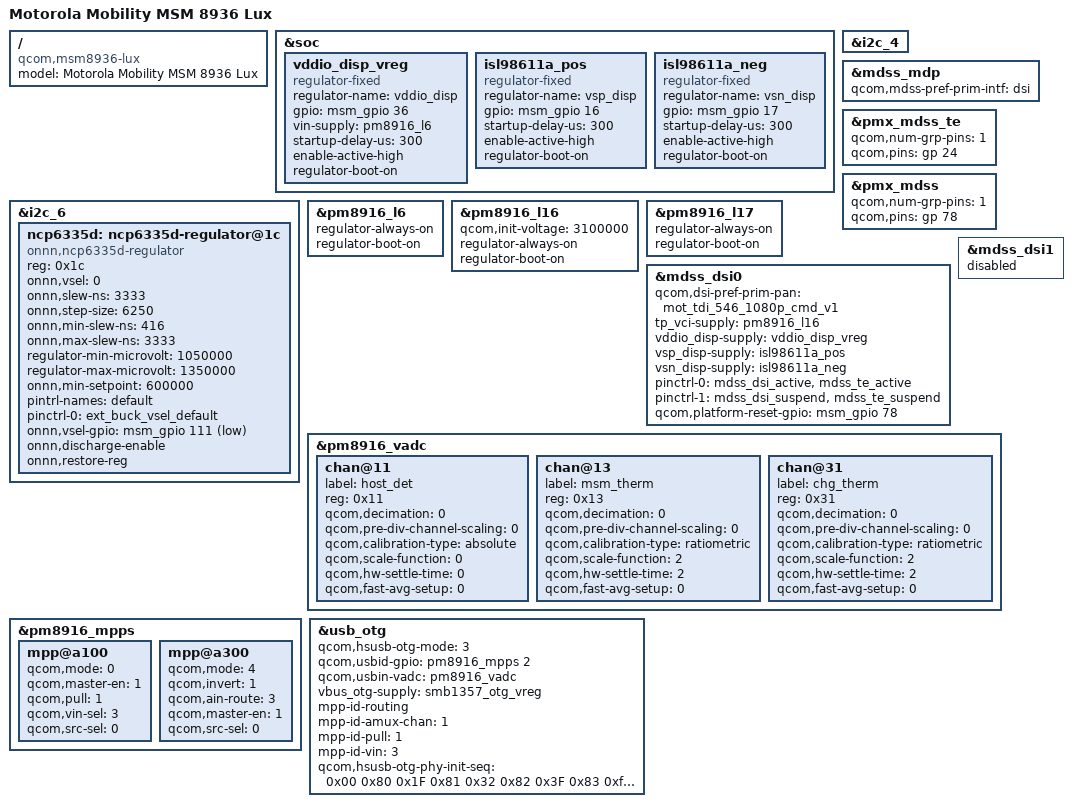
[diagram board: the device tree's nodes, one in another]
/* Copyright (c) 2014, Motorola Mobility LLC. All rights reserved.
*
* This program is free software; you can redistribute it and/or modify
* it under the terms of the GNU General Public License version 2 and
* only version 2 as published by the Free Software Foundation.
*
* This program is distributed in the hope that it will be useful,
* but WITHOUT ANY WARRANTY; without even the implied warranty of
* MERCHANTABILITY or FITNESS FOR A PARTICULAR PURPOSE.  See the
* GNU General Public License for more details.
*/

#include "msm8939-moto-common.dtsi"
#include "dsi-panel-mot-tdi-546-1080p-cmd.dtsi"
#include "dsi-panel-mot-dummy-qhd-video.dtsi"

/ {
	model = "Motorola Mobility MSM 8936 Lux";
	compatible = "qcom,msm8936-lux", "qcom,msm8936-moto", "qcom,msm8936";
};

&soc {
	vddio_disp_vreg: vddio_disp_vreg {
		compatible = "regulator-fixed";
		regulator-name = "vddio_disp";
		gpio = <&msm_gpio 36 0>;
		vin-supply = <&pm8916_l6>;
		startup-delay-us = <300>;
		enable-active-high;
		regulator-boot-on;
	};

	isl98611a_pos: isl98611a_pos {
		compatible = "regulator-fixed";
		regulator-name = "vsp_disp";
		gpio = <&msm_gpio 16 0>;
		startup-delay-us = <300>;
		enable-active-high;
		regulator-boot-on;
	};

	isl98611a_neg: isl98611a_neg {
		compatible = "regulator-fixed";
		regulator-name = "vsn_disp";
		gpio = <&msm_gpio 17 0>;
		startup-delay-us = <300>;
		enable-active-high;
		regulator-boot-on;
	};
};

&i2c_4 {
	/delete-node/ ncp6335d-regulator@1c;
};

&i2c_6 {

	ncp6335d: ncp6335d-regulator@1c {
		compatible = "onnn,ncp6335d-regulator";
		reg = <0x1c>;
		onnn,vsel = <0>;
		onnn,slew-ns = <3333>;
		onnn,step-size = <6250>;
		onnn,min-slew-ns = <416>;
		onnn,max-slew-ns = <3333>;
		regulator-min-microvolt = <1050000>;
		regulator-max-microvolt = <1350000>;
		onnn,min-setpoint = <600000>;
		pintrl-names = "default";
		pinctrl-0 = <&ext_buck_vsel_default>;
		onnn,vsel-gpio = <&msm_gpio 111 1>;
		onnn,discharge-enable;
		onnn,restore-reg;
	};
};


&mdss_mdp {
	qcom,mdss-pref-prim-intf = "dsi";
};

&pmx_mdss_te {
	qcom,num-grp-pins = <1>;
	qcom,pins = <&gp 24>;
};

&pmx_mdss {
	qcom,num-grp-pins = <1>;
	qcom,pins = <&gp 78>;
};

&pm8916_l6 {
	regulator-always-on;
	regulator-boot-on;
};

&pm8916_l16 {
	qcom,init-voltage = <3100000>;
	regulator-always-on;
	regulator-boot-on;
};

&pm8916_l17 {
	regulator-always-on;
	regulator-boot-on;
};

&mdss_dsi0 {
	qcom,dsi-pref-prim-pan = <&mot_tdi_546_1080p_cmd_v1>;
	tp_vci-supply = <&pm8916_l16>;
	vddio_disp-supply = <&vddio_disp_vreg>;
	vsp_disp-supply = <&isl98611a_pos>;
	vsn_disp-supply = <&isl98611a_neg>;

	pinctrl-names = "mdss_default", "mdss_sleep";
	pinctrl-0 = <&mdss_dsi_active &mdss_te_active>;
	pinctrl-1 = <&mdss_dsi_suspend &mdss_te_suspend>;
	qcom,platform-reset-gpio = <&msm_gpio 78 0>;
};

&mdss_dsi1 {
	status = "disabled";
};

&pm8916_vadc {
	/delete-node/ chan@b;

	chan@11 {
		label = "host_det";
		reg = <0x11>;
		qcom,decimation = <0>;
		qcom,pre-div-channel-scaling = <0>;
		qcom,calibration-type = "absolute";
		qcom,scale-function = <0>;
		qcom,hw-settle-time = <0>;
		qcom,fast-avg-setup = <0>;
	};

	chan@13 {
		label = "msm_therm";
		reg = <0x13>;
		qcom,decimation = <0>;
		qcom,pre-div-channel-scaling = <0>;
		qcom,calibration-type = "ratiometric";
		qcom,scale-function = <2>;
		qcom,hw-settle-time = <2>;
		qcom,fast-avg-setup = <0>;
	};

	chan@31 {
		label = "chg_therm";
		reg = <0x31>;
		qcom,decimation = <0>;
		qcom,pre-div-channel-scaling = <0>;
		qcom,calibration-type = "ratiometric";
		qcom,scale-function = <2>;
		qcom,hw-settle-time = <2>;
		qcom,fast-avg-setup = <0>;
	};
};

&pm8916_mpps {
	mpp@a100 { /* MPP 2 */
		status = "okay";
		qcom,mode = <0>; /* DIG_IN input */
		qcom,master-en = <1>; /* Enable MPP */
		qcom,pull = <1>;          /* QPNP_PIN_MPP_PULL_UP_OPEN */
		qcom,vin-sel = <3>;       /* LDO6 1.8V */
		qcom,src-sel = <0>;       /* Constant */
	};
	mpp@a300 { /* MPP 4 */
		status = "okay";
		qcom,mode = <4>; /* AIN input */
		qcom,invert = <1>; /* Enable MPP */
		qcom,ain-route = <3>; /* AMUX 8 */
		qcom,master-en = <1>; /* Enable MPP */
		qcom,src-sel = <0>; /* Function constant */
	};
};

&usb_otg {
	qcom,hsusb-otg-mode = <3>;
	qcom,usbid-gpio = <&pm8916_mpps 2 0>;
	qcom,usbin-vadc = <&pm8916_vadc>;
	vbus_otg-supply = <&smb1357_otg_vreg>;
	mpp-id-routing;
	mpp-id-amux-chan = <1>;              /* QPNP_PIN_AIN_AMUX_CH6 */
	mpp-id-pull = <1>;                   /* QPNP_PIN_MPP_PULL_UP_OPEN */
	mpp-id-vin = <3>;                    /* LDO6 1.8V */
	qcom,hsusb-otg-phy-init-seq =
		<0x00 0x80 0x1F 0x81 0x32 0x82 0x3F 0x83 0xffffffff>;
};
